# PIC32MX470F512L register map
Registers are 32-bit, access not given, reset 0x0 unless marked. A register's access mark holds for its fields unless they carry their own. Offsets are from the block's base; [hi:lo] are bit positions; {n}, {i} and the like mark numbered series; 'fields as' and 'values as' point back to an identical list.

## PCACHE — PCACHE peripheral
Base 0xBF884000
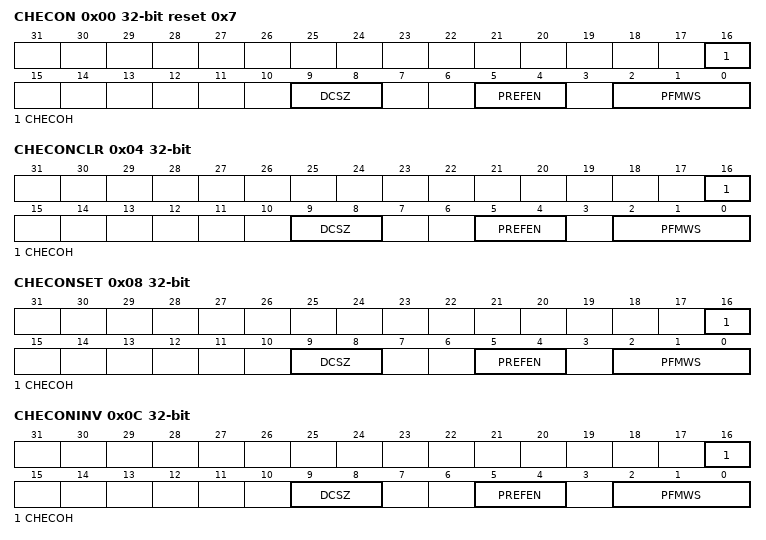
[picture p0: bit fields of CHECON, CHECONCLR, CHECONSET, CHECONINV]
0x00 CHECON reset 0x7
  [16] CHECOH, [9:8] DCSZ, [5:4] PREFEN, [2:0] PFMWS
0x04 CHECONCLR
  [16] CHECOH, [9:8] DCSZ, [5:4] PREFEN, [2:0] PFMWS
0x08 CHECONSET
  [16] CHECOH, [9:8] DCSZ, [5:4] PREFEN, [2:0] PFMWS
0x0C CHECONINV
  [16] CHECOH, [9:8] DCSZ, [5:4] PREFEN, [2:0] PFMWS
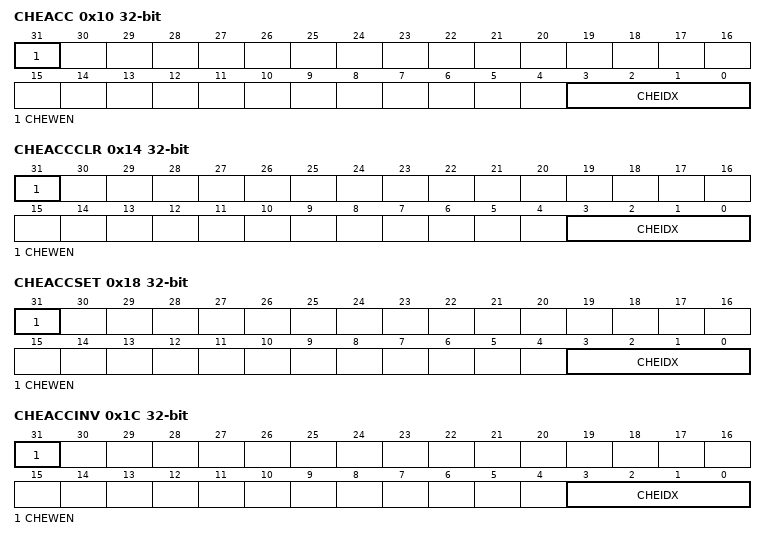
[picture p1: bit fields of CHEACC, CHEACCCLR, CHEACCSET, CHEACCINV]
0x10 CHEACC
  [31] CHEWEN, [3:0] CHEIDX
0x14 CHEACCCLR
  [31] CHEWEN, [3:0] CHEIDX
0x18 CHEACCSET
  [31] CHEWEN, [3:0] CHEIDX
0x1C CHEACCINV
  [31] CHEWEN, [3:0] CHEIDX
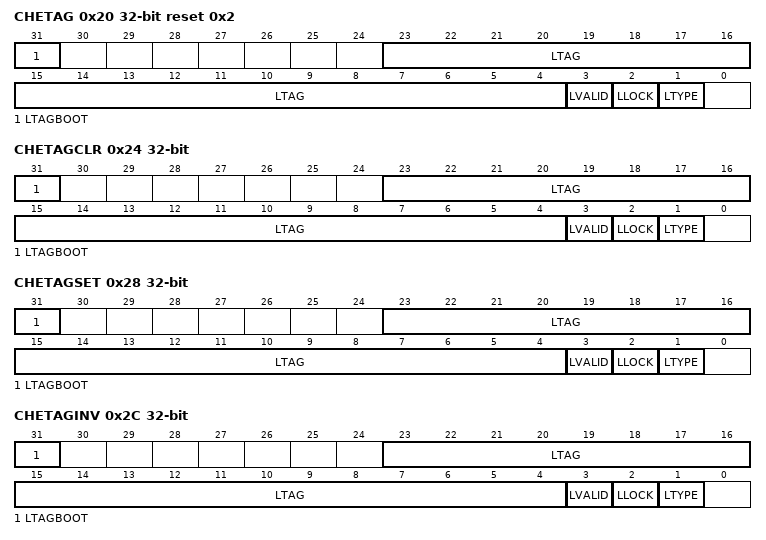
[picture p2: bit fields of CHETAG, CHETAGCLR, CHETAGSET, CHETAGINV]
0x20 CHETAG reset 0x2
  [31] LTAGBOOT, [23:4] LTAG, [3] LVALID, [2] LLOCK, [1] LTYPE
0x24 CHETAGCLR
  [31] LTAGBOOT, [23:4] LTAG, [3] LVALID, [2] LLOCK, [1] LTYPE
0x28 CHETAGSET
  [31] LTAGBOOT, [23:4] LTAG, [3] LVALID, [2] LLOCK, [1] LTYPE
0x2C CHETAGINV
  [31] LTAGBOOT, [23:4] LTAG, [3] LVALID, [2] LLOCK, [1] LTYPE
0x30 CHEMSK
  [15:5] LMASK
0x34 CHEMSKCLR
  [15:5] LMASK
0x38 CHEMSKSET
  [15:5] LMASK
0x3C CHEMSKINV
  [15:5] LMASK
{0x40+0x10*i} CHEW{i} (i=0..3)
0x80 CHELRU
  [24:0] CHELRU
0x90 CHEHIT
0xA0 CHEMIS
0xC0 CHEPFABT

## PORTA — PORTA peripheral
Base 0xBF886000
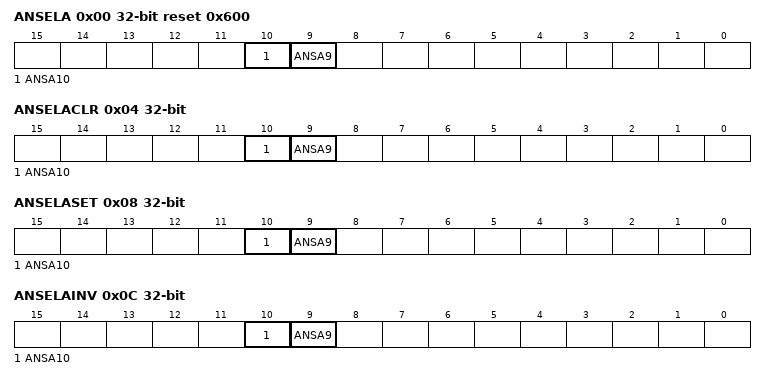
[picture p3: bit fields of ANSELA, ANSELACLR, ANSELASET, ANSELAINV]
0x00 ANSELA reset 0x600
  [10] ANSA10, [9] ANSA9
0x04 ANSELACLR
  [10] ANSA10, [9] ANSA9
0x08 ANSELASET
  [10] ANSA10, [9] ANSA9
0x0C ANSELAINV
  [10] ANSA10, [9] ANSA9
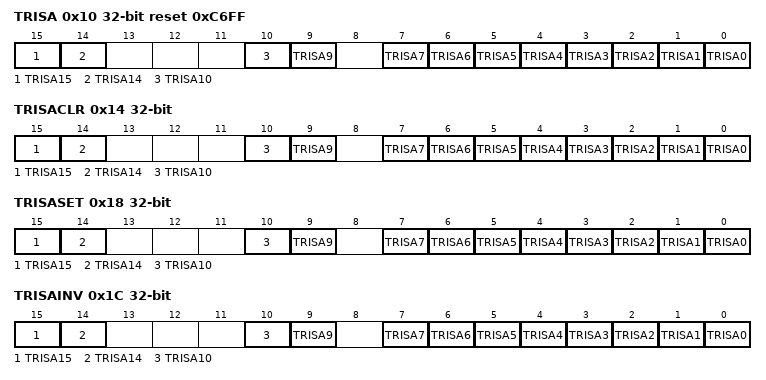
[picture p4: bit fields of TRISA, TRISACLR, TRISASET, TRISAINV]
0x10 TRISA reset 0xC6FF
  [15] TRISA15, [14] TRISA14, [10] TRISA10, [9] TRISA9, [n] TRISA{n} (n=0..7)
0x14 TRISACLR
  fields as TRISA
0x18 TRISASET
  fields as TRISA
0x1C TRISAINV
  fields as TRISA
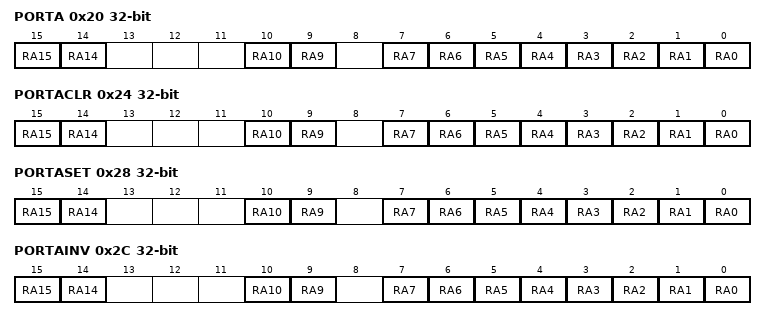
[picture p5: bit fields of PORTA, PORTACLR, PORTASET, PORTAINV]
0x20 PORTA
  [15] RA15, [14] RA14, [10] RA10, [9] RA9, [n] RA{n} (n=0..7)
0x24 PORTACLR
  [15] RA15, [14] RA14, [10] RA10, [9] RA9, [n] RA{n} (n=0..7)
0x28 PORTASET
  [15] RA15, [14] RA14, [10] RA10, [9] RA9, [n] RA{n} (n=0..7)
0x2C PORTAINV
  [15] RA15, [14] RA14, [10] RA10, [9] RA9, [n] RA{n} (n=0..7)
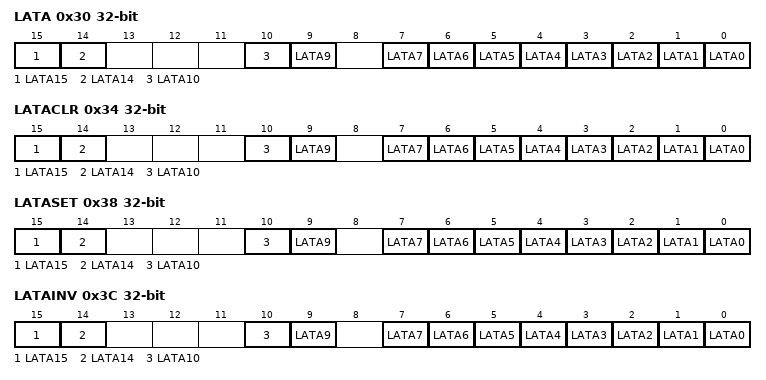
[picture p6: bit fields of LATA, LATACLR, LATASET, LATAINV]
0x30 LATA
  [15] LATA15, [14] LATA14, [10] LATA10, [9] LATA9, [n] LATA{n} (n=0..7)
0x34 LATACLR
  fields as LATA
0x38 LATASET
  fields as LATA
0x3C LATAINV
  fields as LATA
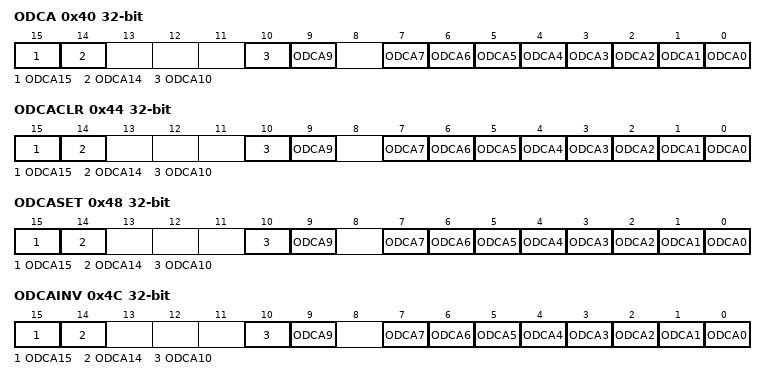
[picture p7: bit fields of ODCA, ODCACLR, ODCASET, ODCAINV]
0x40 ODCA
  [15] ODCA15, [14] ODCA14, [10] ODCA10, [9] ODCA9, [n] ODCA{n} (n=0..7)
0x44 ODCACLR
  fields as ODCA
0x48 ODCASET
  fields as ODCA
0x4C ODCAINV
  fields as ODCA
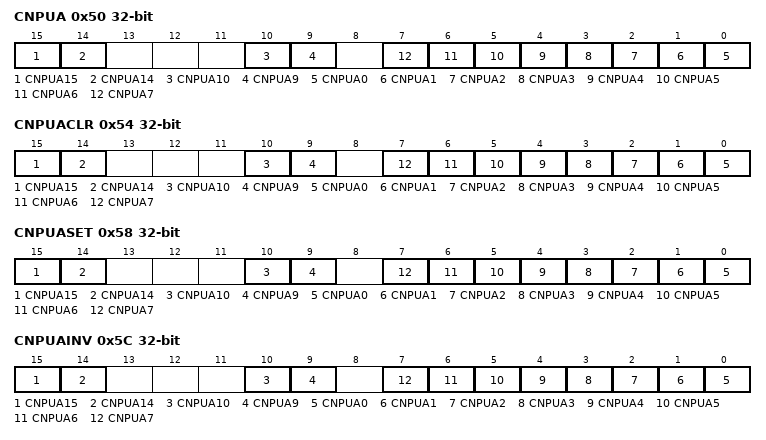
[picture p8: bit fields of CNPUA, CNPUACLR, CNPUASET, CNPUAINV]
0x50 CNPUA
  [15] CNPUA15, [14] CNPUA14, [10] CNPUA10, [9] CNPUA9, [n] CNPUA{n} (n=0..7)
0x54 CNPUACLR
  fields as CNPUA
0x58 CNPUASET
  fields as CNPUA
0x5C CNPUAINV
  fields as CNPUA
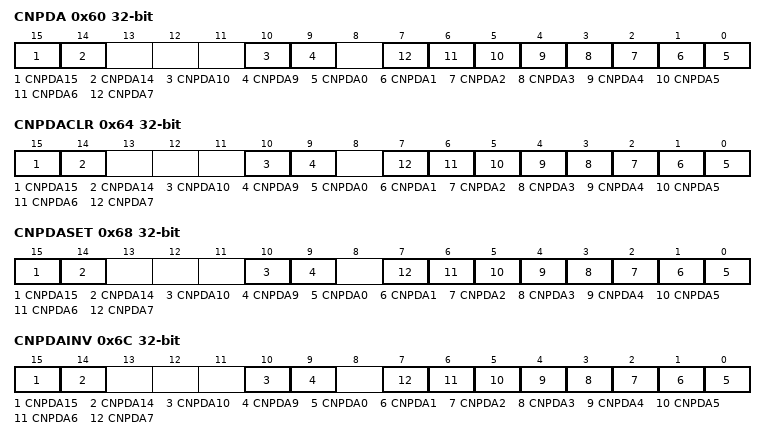
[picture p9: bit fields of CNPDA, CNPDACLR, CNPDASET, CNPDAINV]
0x60 CNPDA
  [15] CNPDA15, [14] CNPDA14, [10] CNPDA10, [9] CNPDA9, [n] CNPDA{n} (n=0..7)
0x64 CNPDACLR
  fields as CNPDA
0x68 CNPDASET
  fields as CNPDA
0x6C CNPDAINV
  fields as CNPDA
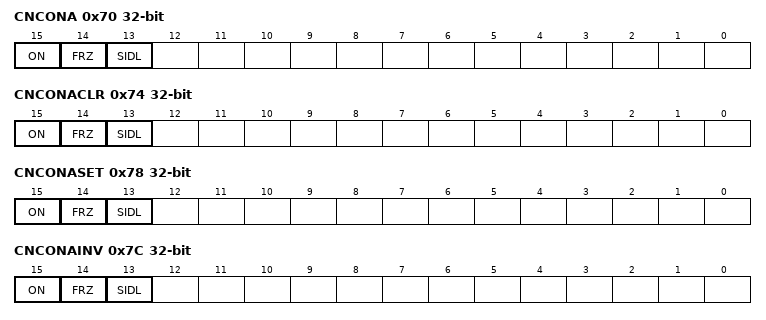
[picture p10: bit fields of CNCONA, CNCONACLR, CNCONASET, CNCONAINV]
0x70 CNCONA
  [15] ON, [14] FRZ, [13] SIDL
0x74 CNCONACLR
  [15] ON, [14] FRZ, [13] SIDL
0x78 CNCONASET
  [15] ON, [14] FRZ, [13] SIDL
0x7C CNCONAINV
  [15] ON, [14] FRZ, [13] SIDL
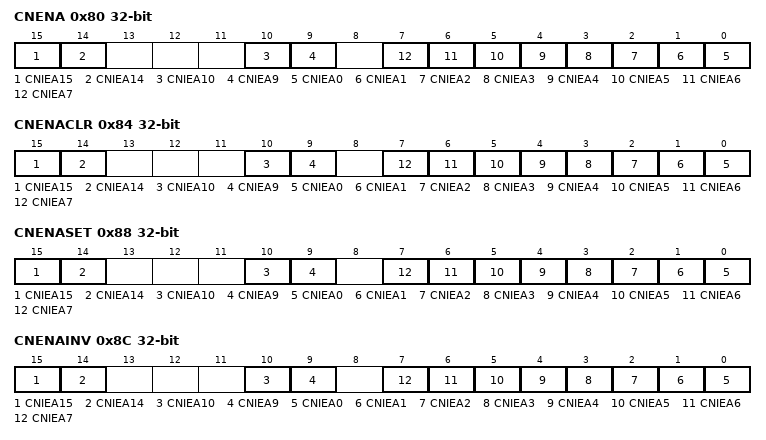
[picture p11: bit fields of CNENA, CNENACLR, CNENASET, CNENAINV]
0x80 CNENA
  [15] CNIEA15, [14] CNIEA14, [10] CNIEA10, [9] CNIEA9, [n] CNIEA{n} (n=0..7)
0x84 CNENACLR
  fields as CNENA
0x88 CNENASET
  fields as CNENA
0x8C CNENAINV
  fields as CNENA
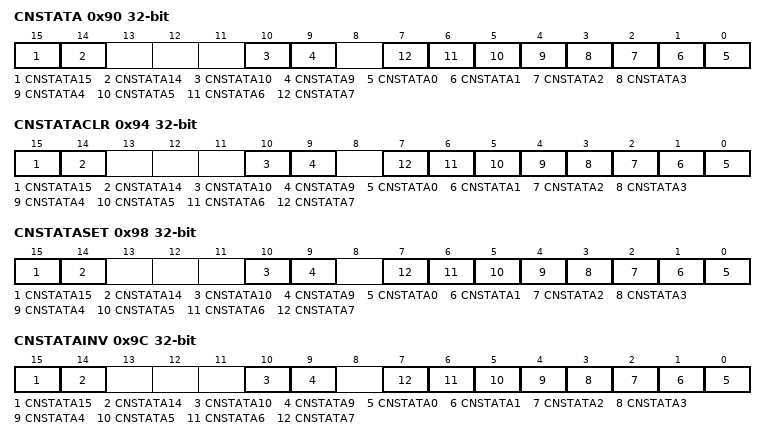
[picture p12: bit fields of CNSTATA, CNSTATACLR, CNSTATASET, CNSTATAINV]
0x90 CNSTATA
  [15] CNSTATA15, [14] CNSTATA14, [10] CNSTATA10, [9] CNSTATA9, [n] CNSTATA{n} (n=0..7)
0x94 CNSTATACLR
  fields as CNSTATA
0x98 CNSTATASET
  fields as CNSTATA
0x9C CNSTATAINV
  fields as CNSTATA

## PORTB — PORTB peripheral
Base 0xBF886100
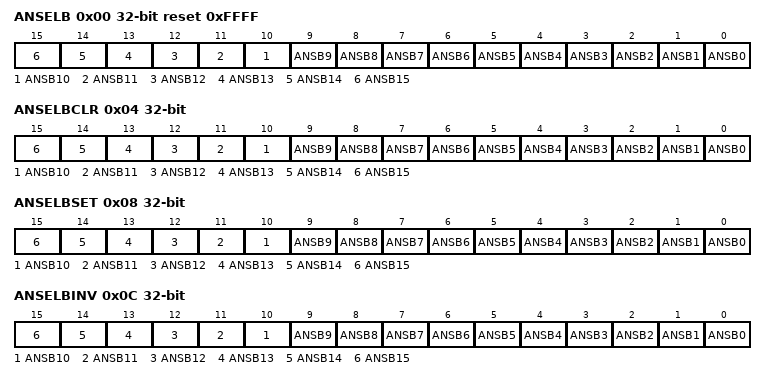
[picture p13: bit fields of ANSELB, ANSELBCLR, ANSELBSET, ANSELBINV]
0x00 ANSELB reset 0xFFFF
  [n] ANSB{n} (n=0..15)
0x04 ANSELBCLR
  [n] ANSB{n} (n=0..15)
0x08 ANSELBSET
  [n] ANSB{n} (n=0..15)
0x0C ANSELBINV
  [n] ANSB{n} (n=0..15)
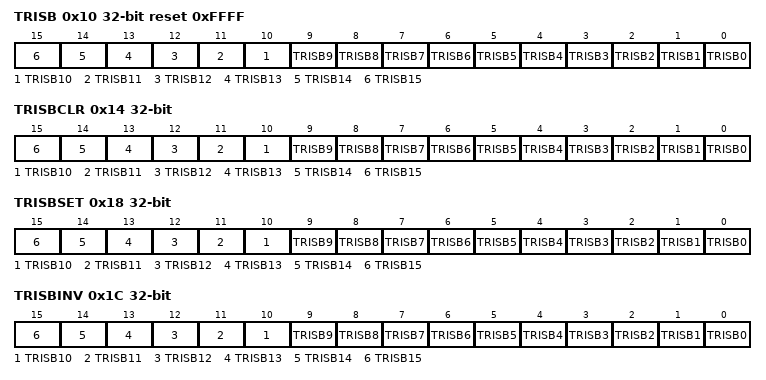
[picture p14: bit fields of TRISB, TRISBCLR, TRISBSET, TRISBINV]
0x10 TRISB reset 0xFFFF
  [n] TRISB{n} (n=0..15)
0x14 TRISBCLR
  [n] TRISB{n} (n=0..15)
0x18 TRISBSET
  [n] TRISB{n} (n=0..15)
0x1C TRISBINV
  [n] TRISB{n} (n=0..15)
0x20 PORTB
  [n] RB{n} (n=0..15)
0x24 PORTBCLR
  [n] RB{n} (n=0..15)
0x28 PORTBSET
  [n] RB{n} (n=0..15)
0x2C PORTBINV
  [n] RB{n} (n=0..15)
0x30 LATB
  [n] LATB{n} (n=0..15)
0x34 LATBCLR
  [n] LATB{n} (n=0..15)
0x38 LATBSET
  [n] LATB{n} (n=0..15)
0x3C LATBINV
  [n] LATB{n} (n=0..15)
0x40 ODCB
  [n] ODCB{n} (n=0..15)
0x44 ODCBCLR
  [n] ODCB{n} (n=0..15)
0x48 ODCBSET
  [n] ODCB{n} (n=0..15)
0x4C ODCBINV
  [n] ODCB{n} (n=0..15)
0x50 CNPUB
  [n] CNPUB{n} (n=0..15)
0x54 CNPUBCLR
  [n] CNPUB{n} (n=0..15)
0x58 CNPUBSET
  [n] CNPUB{n} (n=0..15)
0x5C CNPUBINV
  [n] CNPUB{n} (n=0..15)
0x60 CNPDB
  [n] CNPDB{n} (n=0..15)
0x64 CNPDBCLR
  [n] CNPDB{n} (n=0..15)
0x68 CNPDBSET
  [n] CNPDB{n} (n=0..15)
0x6C CNPDBINV
  [n] CNPDB{n} (n=0..15)
0x70 CNCONB
  [15] ON, [14] FRZ, [13] SIDL
0x74 CNCONBCLR
  [15] ON, [14] FRZ, [13] SIDL
0x78 CNCONBSET
  [15] ON, [14] FRZ, [13] SIDL
0x7C CNCONBINV
  [15] ON, [14] FRZ, [13] SIDL
0x80 CNENB
  [n] CNIEB{n} (n=0..15)
0x84 CNENBCLR
  [n] CNIEB{n} (n=0..15)
0x88 CNENBSET
  [n] CNIEB{n} (n=0..15)
0x8C CNENBINV
  [n] CNIEB{n} (n=0..15)
0x90 CNSTATB
  [n] CNSTATB{n} (n=0..15)
0x94 CNSTATBCLR
  [n] CNSTATB{n} (n=0..15)
0x98 CNSTATBSET
  [n] CNSTATB{n} (n=0..15)
0x9C CNSTATBINV
  [n] CNSTATB{n} (n=0..15)
